# PT32x012xx register map
File version: 0.2
Registers are 32-bit, read-write, reset 0x0 unless marked. A register's access mark holds for its fields unless they carry their own. Offsets are from the block's base; [hi:lo] are bit positions; {n}, {i} and the like mark numbered series.

## TIM20 — Advanced timer
Base 0x40007400
Same registers: TIM22 0x40007C00
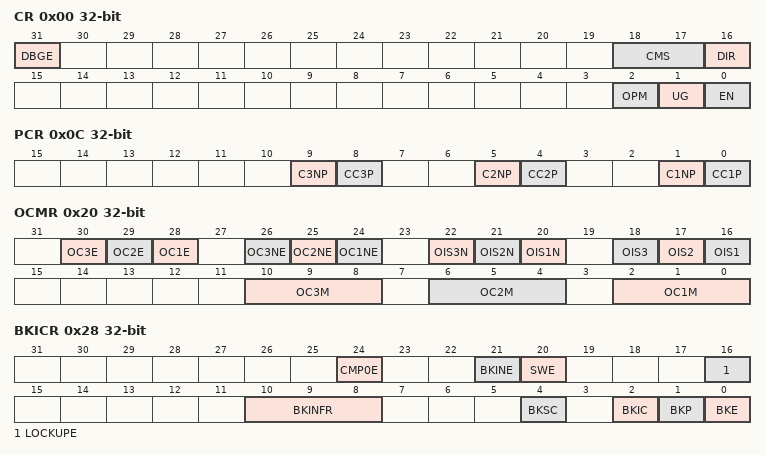
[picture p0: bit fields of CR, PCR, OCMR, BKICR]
0x00 CR access per field — Control Register
  [31] DBGE rw — TIM debug
  [18:17] CMS rw — Center-aligned mode selection
  [16] DIR rw — Direction
  [2] OPM rw — One-pulse mode
  [1] UG wo — Update generation
  [0] EN rw — TIM enable
0x0C PCR — Polarity Control Register
  [9] C3NP — Compare 3 complementary output polarity
  [8] CC3P — Capture/Compare 3 output polarity
  [5] C2NP — Compare 2 complementary output polarity
  [4] CC2P — Capture/Compare 2 output polarity
  [1] C1NP — Compare 1 complementary output polarity
  [0] CC1P — Capture/Compare 1 output polarity
0x20 OCMR — Output Compare Mode Register
  [30] OC3E — Compare output 3 output enable
  [29] OC2E — Compare output 2 output enable
  [28] OC1E — Compare output 1 output enable
  [26] OC3NE — Compare output 3 complementary output enable
  [25] OC2NE — Compare output 2 complementary output enable
  [24] OC1NE — Compare output 1 complementary output enable
  [22] OIS3N — Output Idle state 3 complementary
  [21] OIS2N — Output Idle state 2 complementary
  [20] OIS1N — Output Idle state 1 complementary
  [18] OIS3 — Output Idle state 3
  [17] OIS2 — Output Idle state 2
  [16] OIS1 — Output Idle state 1
  [10:8] OC3M — output compare 3 mode
  [6:4] OC2M — output compare 2 mode
  [2:0] OC1M — output compare 1 mode
0x28 BKICR — Break Input Control Register
  [24] CMP0E — CMP0 Break input enable
  [21] BKINE — BKIN Break input enable
  [20] SWE — SW Break input enable
  [16] LOCKUPE — LOCKUP break input enable
  [10:8] BKINFR — BKIN Input filter
  [4] BKSC — Break software control enable
  [2] BKIC — break input control
  [1] BKP — Break polarity
  [0] BKE — Break enable
0x2C DTCR — Dead Time Control Register
  [11:0] DT — Dead-time value
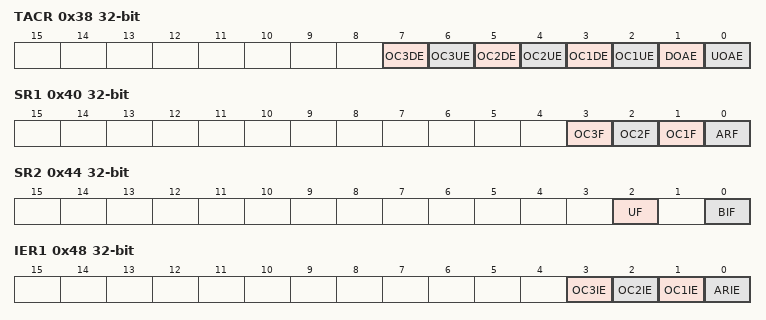
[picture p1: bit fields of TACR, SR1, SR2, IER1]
0x38 TACR — Regular Trigger ADC Control Register
  [7] OC3DE — OC3D trigger ADC enable
  [6] OC3UE — OC3U trigger ADC enable
  [5] OC2DE — OC2D trigger ADC enable
  [4] OC2UE — OC2U trigger ADC enable
  [3] OC1DE — OC1D trigger ADC enable
  [2] OC1UE — OC1U trigger ADC enable
  [1] DOAE — DownOVF trigger ADC enable
  [0] UOAE — UpOVF trigger ADC enable
0x40 SR1 — Status Register 1
  [3] OC3F — Output compare 3 flag
  [2] OC2F — Output compare 2 flag
  [1] OC1F — Output compare 1 flag
  [0] ARF — Auto reload flag
0x44 SR2 — Status Register 2
  [2] UF — update flag
  [0] BIF — Break input flag
0x48 IER1 — Interrupt Enable Register 1
  [3] OC3IE — output compare 3 interrupt enable
  [2] OC2IE — output compare 2 interrupt enable
  [1] OC1IE — output compare 1 interrupt enable
  [0] ARIE — Auto reload interrupt enable
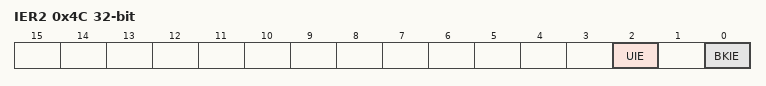
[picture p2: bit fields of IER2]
0x4C IER2 — Interrupt Enable Register 2
  [2] UIE — Update interrupt enable
  [0] BKIE — Break interrupt enable
0x50 ITARR — Interrupt Auto Reload Register
  [3:0] ITARR — TIM interrupt auto reload
0x54 ITCNTR ro — Interrupt Counter Register
  [3:0] ITCNT — TIM interrupt counter value
0x58 PSCR — Prescaler Register
  [15:0] PSC — Prescaler value
0x60 CNTR — Counter Register
  [15:0] CNT — Counter value
0x64 ARR — Auto Reload Register
  [15:0] ARR — Auto reload value
{0x64+4i} OCR{i} (i=1..3) — Output Compare Register {i}
  [15:0] OCR — output compare value

## TIM21 — Advanced timer
Base 0x40007800
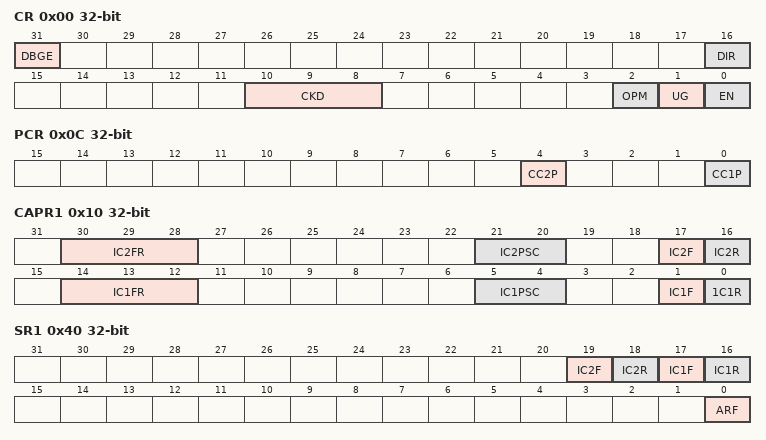
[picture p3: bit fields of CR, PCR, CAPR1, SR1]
0x00 CR access per field — Control Register
  [31] DBGE rw — TIM debug
  [16] DIR rw — Direction
  [10:8] CKD rw — Sampling clock division
  [2] OPM rw — One-pulse mode
  [1] UG wo — Update generation
  [0] EN rw — TIM enable
0x0C PCR — Polarity Control Register
  [4] CC2P — Capture/Compare 2 output polarity
  [0] CC1P — Capture/Compare 1 output polarity
0x10 CAPR1 — Capture Configuration Register 1
  [30:28] IC2FR — Input capture 2 filter
  [21:20] IC2PSC — Input capture 2 prescaler
  [17] IC2F — input capture 2 falling capture enable
  [16] IC2R — input capture 2 rising capture enable
  [14:12] IC1FR — Input capture 1 filter
  [5:4] IC1PSC — Input capture 1 prescaler
  [1] IC1F — input capture 1 falling capture enable
  [0] 1C1R — input capture 1 rising capture enable
0x40 SR1 — Status Register 1
  [19] IC2F — input capture 2 falling edge flag
  [18] IC2R — input capture 2 rising edge flag
  [17] IC1F — input capture 1 falling edge flag
  [16] IC1R — input capture 1 rising edge flag
  [0] ARF — Auto reload flag
0x44 SR2 — Status Register 2
  [2] UF — update flag
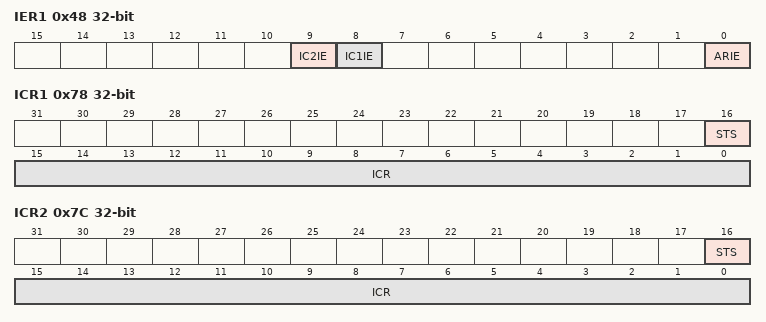
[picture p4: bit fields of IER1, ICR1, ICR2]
0x48 IER1 — Interrupt Enable Register 1
  [9] IC2IE — input capture 2 interrupt enable
  [8] IC1IE — input capture 1 interrupt enable
  [0] ARIE — Auto reload interrupt enable
0x4C IER2 — Interrupt Enable Register 2
  [2] UIE — Update interrupt enable
0x58 PSCR — Prescaler Register
  [15:0] PSC — Prescaler value
0x60 CNTR — Counter Register
  [15:0] CNT — Counter value
0x64 ARR — Auto Reload Register
  [15:0] ARR — Auto reload value
0x78 ICR1 ro — Input Capture Register 1
  [16] STS — input capture status
  [15:0] ICR — input capture value
0x7C ICR2 ro — Input Capture Register 2
  [16] STS — input capture status
  [15:0] ICR — input capture value
